# DA14681 register map
Vendor: Dialog; Series: DA14681; File version: 1.2
CPU: CM0 r1p0, little endian, MPU, FPU, 3 interrupt priority bits
Registers are 16-bit, read-write, reset 0x0 unless marked. A register's access mark holds for its fields unless they carry their own. Offsets are from the block's base; [hi:lo] are bit positions; {n}, {i} and the like mark numbered series; 'fields as' and 'values as' point back to an identical list.

## FTDF — FTDF registers
Base 0x40080000
{0x0+0x80*i} FTDF_TX_FIFO_{i}_0_REG 32-bit (reset mask 0x7FFFFFFF) (i=0..3) — Address transmit fifo {i}
  [31:0] TX_FIFO — Transmit fifo buffer, contains 32 addresses per entry (32b x 32a = 128B). There are 4 entries supported.
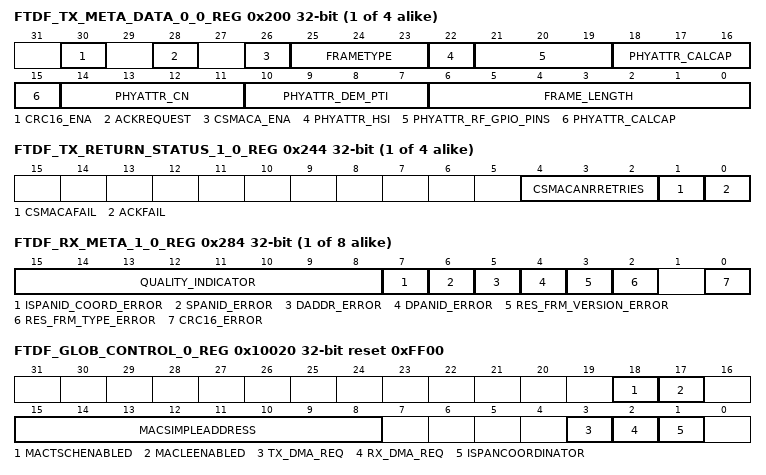
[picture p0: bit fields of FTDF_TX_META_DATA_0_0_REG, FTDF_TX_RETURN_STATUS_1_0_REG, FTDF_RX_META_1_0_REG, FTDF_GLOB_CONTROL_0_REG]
{0x200+0x10*i} FTDF_TX_META_DATA_0_{i}_REG 32-bit (i=0..3) — Transmit metadata register {i}
  [30] CRC16_ENA — Indicates whether CRC16 insertion must be enabled or not. 0 : No hardware inserted CRC16 1 : Hardware inserts CRC16
  [28] ACKREQUEST — Indicates whether an acknowledge is expected from the recipient of this packet.
  [26] CSMACA_ENA — Indicates whether a CSMA-CA is required for the transmission of this packet.
  [25:23] FRAMETYPE — Data/Cmd/Ack etc. Also indicate wakeup frame
  [22] PHYATTR_HSI — HighSide injection.
  [21:19] PHYATTR_RF_GPIO_PINS — Slot-basis signals mapped on GPIO via PPA.
  [18:15] PHYATTR_CALCAP — CalCap value.
  [14:11] PHYATTR_CN — Channel Number.
  [10:7] PHYATTR_DEM_PTI — DEM packet information.
  [6:0] FRAME_LENGTH
{0x204+0x10*i} FTDF_TX_META_DATA_1_{i}_REG 32-bit (i=0..3) — Transmit metadata register {i}
  [7:0] MACSN — Sequence Number of this packet.
{0x240+0x10*i} FTDF_TX_RETURN_STATUS_0_{i}_REG 32-bit (reset mask 0x7FFFFFFF) (i=0..3) — Transmit status register {i}
  [31:0] TXTIMESTAMP ro — Transmit Timestamp The TimeStamp of the transmitted packet.
{0x244+0x10*i} FTDF_TX_RETURN_STATUS_1_{i}_REG 32-bit (i=0..3) — Transmit status register {i}
  [4:2] CSMACANRRETRIES ro — Number of CSMA-CA retries
  [1] CSMACAFAIL ro — CSMA-CA status 0 : SUCCESS 1 : FAIL
  [0] ACKFAIL ro — Acknowledgement status 0 : SUCCESS 1 : FAIL
{0x280+0x10*i} FTDF_RX_META_0_{i}_REG 32-bit (reset mask 0x7FFFFFFF) (i=0..7) — Receive metadata register {i}
  [31:0] RX_TIMESTAMP ro — Timestamp taken when frame was received
{0x284+0x10*i} FTDF_RX_META_1_{i}_REG 32-bit (i=0..7) — Receive metadata register {i}
  [15:8] QUALITY_INDICATOR ro — Link Quality Indication # $software_scratch@retention_ram # TX ram not used by hardware, can be used by software as scratch ram with retention.
  [7] ISPANID_COORD_ERROR ro — Received frame not for PAN coordinator, applicable when frame is not discarded
  [6] SPANID_ERROR ro — PAN ID error, applicable when frame is not discarded
  [5] DADDR_ERROR ro — D Address error, applicable when frame is not discarded
  [4] DPANID_ERROR ro — D PAN ID error, applicable when frame is not discarded
  [3] RES_FRM_VERSION_ERROR ro — Not supported frame version error, applicable when frame is not discarded.
  [2] RES_FRM_TYPE_ERROR ro — Not supported frame type error, applicable when frame is not discarded
  [0] CRC16_ERROR ro — CRC error, applicable for transparent mode only
0x8000 FTDF_RX_FIFO_0_0_REG 32-bit (reset mask 0x7FFFFFFF) — Address receive fifo 0
  [31:0] RX_FIFO — Receive fifo ram, contains 32 addresses per entry (32b x 32a = 128B). There are 8 entries supported.
{0x8000+0x80*i} FTDF_RX_FIFO_{i}_0_REG 32-bit (reset mask 0x7FFFFFFF) (i=1..7) — Address transmit fifo {i}
  fields as FTDF_RX_FIFO_0_0_REG
{0x10000+4i} FTDF_REL_NAME_{i}_REG 32-bit (reset mask 0x7FFFFFFF) (i=0..3) — Name of the release
  [31:0] REL_NAME ro
{0x10010+4i} FTDF_BUILDTIME_{i}_REG 32-bit (reset mask 0x7FFFFFFF) (i=0..3) — Build time
  [31:0] BUILDTIME ro — Build time of device
0x10020 FTDF_GLOB_CONTROL_0_REG 32-bit reset 0xFF00 — Global control register
  [18] MACTSCHENABLED — If set, TSCH mode is enabled
  [17] MACLEENABLED — If set, Low Energy mode is enabled
  [15:8] MACSIMPLEADDRESS — Simple address of the PAN coordinator
  [3] TX_DMA_REQ — Source of the TX_DMA_REQ output of this block.
  [2] RX_DMA_REQ — Source of the RX_DMA_REQ output of this block.
  [1] ISPANCOORDINATOR — Enable/disable receiver check on address fields (0=enabled, 1=disabled)
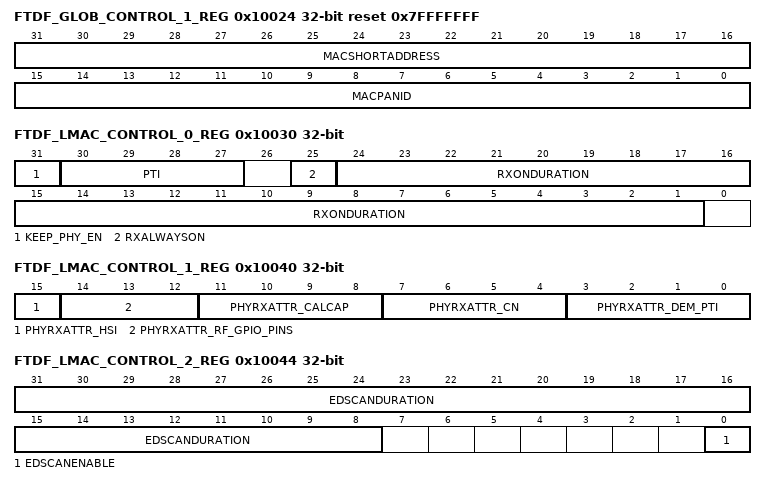
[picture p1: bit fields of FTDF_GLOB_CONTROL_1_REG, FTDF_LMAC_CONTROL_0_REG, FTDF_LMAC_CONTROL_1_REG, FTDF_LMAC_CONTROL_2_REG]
0x10024 FTDF_GLOB_CONTROL_1_REG 32-bit reset 0x7FFFFFFF (reset mask 0x7FFFFFFF) — Global control register
  [31:16] MACSHORTADDRESS — The values 0xFFFF and 0xFFFE indicate that no IEEE Short Address is available. The latter one is used if the device i
  [15:0] MACPANID — The values 0xFFFF indicates that the device is not associated
0x10028 FTDF_GLOB_CONTROL_2_REG 32-bit reset 0x7FFFFFFF (reset mask 0x7FFFFFFF) — Global control register
  [31:0] AEXTENDEDADDRESS_L — Unique device address, lower 32 bit
0x1002C FTDF_GLOB_CONTROL_3_REG 32-bit reset 0x7FFFFFFF (reset mask 0x7FFFFFFF) — Global control register
  [31:0] AEXTENDEDADDRESS_H — Unique device address, higher 16 bit
0x10030 FTDF_LMAC_CONTROL_0_REG 32-bit (reset mask 0x7FFFFFFF) — Lmac control register
  [31] KEEP_PHY_EN — When the transmit or receive action is ready (LmacReady4Sleep will is set), the phy_en signal is cleared unless the control register keep_phy_en is set. When the control register keep_phy_en is set, the signal phy_en shall remain being set until the keep_phy_en is cleared.
  [30:27] PTI — Info to arbiter if phy_en is set
  [25] RXALWAYSON — If set, the receiver shall be always on if RxEnable is set
  [24:1] RXONDURATION — Time the Rx must be on
0x10034 FTDF_TXPIPEPROPDELAY_REG 32-bit — Prop delay transmit register
  [7:0] TXPIPEPROPDELAY — Prop delay of tx pipe, start to DPHY
0x10038 FTDF_MACACKWAITDURATION_REG 32-bit reset 0x36 — Maximum time to wait for a ACK
  [7:0] MACACKWAITDURATION — Max time to wait for a (normal) ACK
0x1003C FTDF_MACENHACKWAITDURATION_REG 32-bit reset 0x360 — Maximum time to wait for an enhanced ACK frame
  [15:0] MACENHACKWAITDURATION — The maximum time (in s) to wait for an enhanced acknowledgement frame
0x10040 FTDF_LMAC_CONTROL_1_REG 32-bit — Lmac control register
  [15] PHYRXATTR_HSI — HighSide injection.
  [14:12] PHYRXATTR_RF_GPIO_PINS — Slot-basis signals mapped on GPIO via PPA.
  [11:8] PHYRXATTR_CALCAP — CalCap value.
  [7:4] PHYRXATTR_CN — Channel Number.
  [3:0] PHYRXATTR_DEM_PTI — DEM packet information.
0x10044 FTDF_LMAC_CONTROL_2_REG 32-bit (reset mask 0x7FFFFFFF) — Lmac control register
  [31:8] EDSCANDURATION — Length of ED scan
  [0] EDSCANENABLE — if set, Energy Detect scan will be done
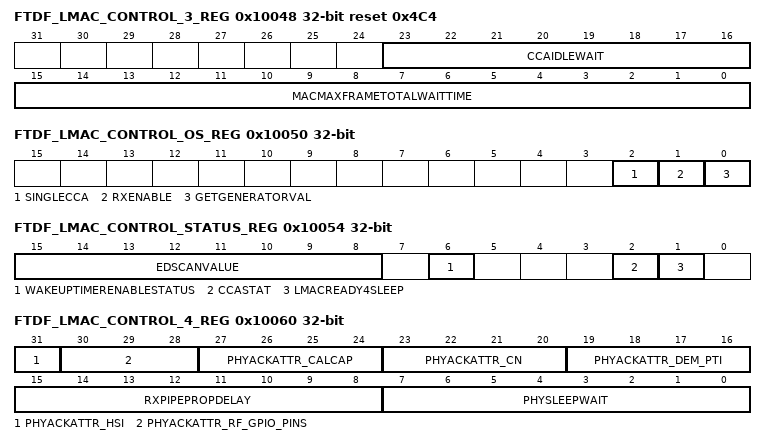
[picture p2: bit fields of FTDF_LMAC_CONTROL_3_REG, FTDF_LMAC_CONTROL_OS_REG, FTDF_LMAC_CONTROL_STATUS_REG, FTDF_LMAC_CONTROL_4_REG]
0x10048 FTDF_LMAC_CONTROL_3_REG 32-bit reset 0x4C4 — Lmac control register
  [23:16] CCAIDLEWAIT — Time to wait after CCA returned "medium idle" before starting TX-ON (in us). Note: not applicable in TSCH mode since there macTSRxTx shall be used.
  [15:0] MACMAXFRAMETOTALWAITTIME — Max time to wait for a requested Data Frame or an announced broadcast frame
0x10050 FTDF_LMAC_CONTROL_OS_REG 32-bit — Lmac control register
  [2] SINGLECCA wo — If set, a single CCA will be performed.
  [1] RXENABLE wo — If set, receiving data may be done
  [0] GETGENERATORVAL wo — If set, the current values of WU gen and TS gen will be captured.
0x10054 FTDF_LMAC_CONTROL_STATUS_REG 32-bit — Lmac status register
  [15:8] EDSCANVALUE ro — Result of ED scan.
  [6] WAKEUPTIMERENABLESTATUS ro — Status of WakeupTimerEnable after being clocked by LP_CLK (showing it's effective value).
  [2] CCASTAT ro — Value single CCA when CCAstat_e is set.
  [1] LMACREADY4SLEEP ro — Indicates that the LMAC is ready to go to sleep.
0x10058 FTDF_EVENTCURRVAL_REG 32-bit (reset mask 0x7FFFFFFF) — Value of event generator
  [31:0] EVENTCURRVAL ro — Value of captured Event generator
0x1005C FTDF_TIMESTAMPCURRVAL_REG 32-bit (reset mask 0x7FFFFFFF) — Value of timestamp generator
  [31:0] TIMESTAMPCURRVAL ro — Value of captured TS gen
0x10060 FTDF_LMAC_CONTROL_4_REG 32-bit (reset mask 0x7FFFFFFF) — Lmac control register
  [31] PHYACKATTR_HSI — HighSide injection.
  [30:28] PHYACKATTR_RF_GPIO_PINS — Slot-basis signals mapped on GPIO via PPA.
  [27:24] PHYACKATTR_CALCAP — CalCap value.
  [23:20] PHYACKATTR_CN — Channel Number.
  [19:16] PHYACKATTR_DEM_PTI — DEM packet information.
  [15:8] RXPIPEPROPDELAY — The control register RxPipePropDelay indicates the propagation delay in ~s of the Rx pipeline between the last symbol being captured at the DPHY interface and the "data valid" indication to the LMAC controller.
  [7:0] PHYSLEEPWAIT — Time between negate and assert PHY_EN When the signal phy_en is deasserted, it will not be asserted within the time phySleepWait. This time is indicated by the control register phySleepWait (resolution: ~s).
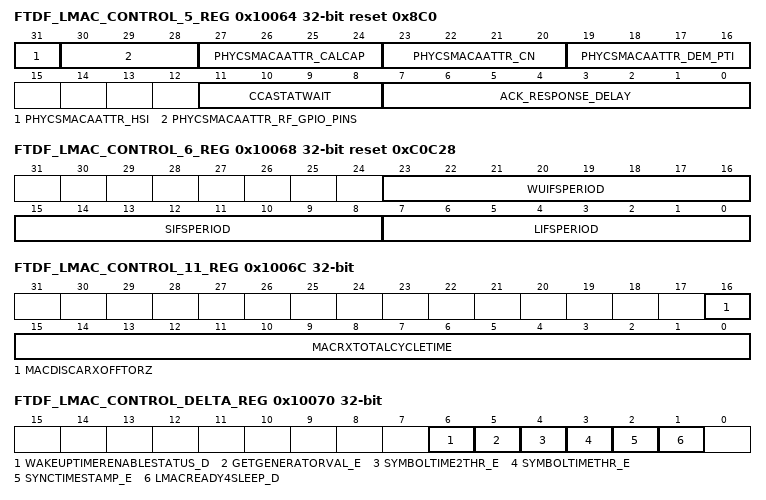
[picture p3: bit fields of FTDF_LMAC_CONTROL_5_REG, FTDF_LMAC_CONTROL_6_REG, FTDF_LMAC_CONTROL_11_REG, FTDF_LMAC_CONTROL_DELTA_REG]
0x10064 FTDF_LMAC_CONTROL_5_REG 32-bit reset 0x8C0 (reset mask 0x7FFFFFFF) — Lmac control register
  [31] PHYCSMACAATTR_HSI — HighSide injection.
  [30:28] PHYCSMACAATTR_RF_GPIO_PINS — Slot-basis signals mapped on GPIO via PPA.
  [27:24] PHYCSMACAATTR_CALCAP — CalCap value.
  [23:20] PHYCSMACAATTR_CN — Channel Number.
  [19:16] PHYCSMACAATTR_DEM_PTI — DEM packet information.
  [11:8] CCASTATWAIT — The output CCASTAT is valid after 8 symbols + phyRxStartup. The 8 symbols are programmable by control registerCcaStatWait[4] in symbol timesl. Default value is 8d.
  [7:0] ACK_RESPONSE_DELAY — In order to have some flexibility the control register Ack_Response_Delay indicates the Acknowledge response time in ~s. The default value shall is 192 ~s (12 symbols).
0x10068 FTDF_LMAC_CONTROL_6_REG 32-bit reset 0xC0C28 — Lmac control register
  [23:16] WUIFSPERIOD — The WakeUp IFS period is programmable by WUifsPeriod (in symbols). The default is 12 symbols (192 ~s).
  [15:8] SIFSPERIOD — The SIFS period is programmable by SifsPeriod (in symbols). The default is 12 symbols (192 ~s).
  [7:0] LIFSPERIOD — The LIFS period is programmable by LifsPeriod (in symbols). The default is 40 symbols (640 ~s),
0x1006C FTDF_LMAC_CONTROL_11_REG 32-bit — Lmac control register
  [16] MACDISCARXOFFTORZ — This switching off and on of the PHY Rx can be disabled whith the control register macDisCaRxOfftoRZ. 0 : Disabled 1 : Enabled
  [15:0] MACRXTOTALCYCLETIME — In order to make it easier to calculate if it is efficient to disable and enable the PHY Rx until the RZ time is reached, a control register indicates the time needed to disable and enable the PHY Rx: macRxTotalCycleTime (resolution in 10 sym)
0x10070 FTDF_LMAC_CONTROL_DELTA_REG 32-bit — Lmac delta control register
  [6] WAKEUPTIMERENABLESTATUS_D — Delta which indicates that WakeupTimerEnableStatus has changed
  [5] GETGENERATORVAL_E — Event which indicates the getGeneratorVal request is completed
  [4] SYMBOLTIME2THR_E — Event that symboltime counter matched SymbolTime2Thr
  [3] SYMBOLTIMETHR_E — Event that symboltime counter matched SymbolTimeThr
  [2] SYNCTIMESTAMP_E — The SyncTimeStamp_e event is set when the TimeStampgenerator is loaded with SyncTimeStampVal. This occurs at the rising edge of lp_clk when SyncTimeStampEna is set and the value of the Event generator is equal to the value SyncTimestampThr.
  [1] LMACREADY4SLEEP_D — Delta bit for register "LmacReady4sleep"
0x10074 FTDF_TIMESTAMPCURRPHASEVAL_REG 32-bit — Value of timestamp generator phase within a symbol
  [7:0] TIMESTAMPCURRPHASEVAL ro — Value of captured TS gen phase within a symbol
0x10078 FTDF_MACTSTXACKDELAYVAL_REG 32-bit — Time left until next ACK is sent (us)
  [15:0] MACTSTXACKDELAYVAL ro — The time in us left until the ack frame is sent by the lmac
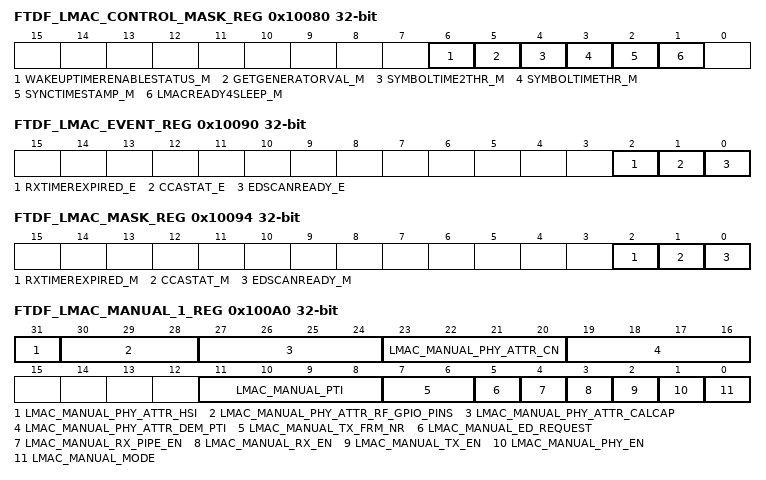
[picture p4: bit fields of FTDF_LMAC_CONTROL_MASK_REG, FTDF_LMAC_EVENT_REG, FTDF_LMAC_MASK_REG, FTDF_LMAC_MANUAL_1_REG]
0x10080 FTDF_LMAC_CONTROL_MASK_REG 32-bit — Lmac mask control register
  [6] WAKEUPTIMERENABLESTATUS_M — Mask for WakeupTimerEnableStatus_d
  [5] GETGENERATORVAL_M — Mask for getGeneratorVal_e
  [4] SYMBOLTIME2THR_M — Mask for SymbolTime2Thr_e
  [3] SYMBOLTIMETHR_M — Mask for SymbolTimeThr_e
  [2] SYNCTIMESTAMP_M — Mask bit for event register SyncTimeStamp_e.
  [1] LMACREADY4SLEEP_M — Mask bit for delta bit "LmacReady4sleep_d"
0x10090 FTDF_LMAC_EVENT_REG 32-bit — Lmac event regsiter
  [2] RXTIMEREXPIRED_E — Set if one of the timers enabling the RX-ON mode expires without having received any valid frame
  [1] CCASTAT_E — If set, the single CCA is ready
  [0] EDSCANREADY_E — The event EdScanReady_e is set to notify that the ED scan is ready.
0x10094 FTDF_LMAC_MASK_REG 32-bit — Lmac mask register
  [2] RXTIMEREXPIRED_M — Mask bit for event "RxTimerExpired_e"
  [1] CCASTAT_M — Mask bit for event "CCAstat_e"
  [0] EDSCANREADY_M — Mask bit for event "EdScanReady_e"
0x100A0 FTDF_LMAC_MANUAL_1_REG 32-bit (reset mask 0x7FFFFFFF) — Lmax manual PHY register
  [31] LMAC_MANUAL_PHY_ATTR_HSI — HighSide injection.
  [30:28] LMAC_MANUAL_PHY_ATTR_RF_GPIO_PINS — Slot-basis signals mapped on GPIO via PPA.
  [27:24] LMAC_MANUAL_PHY_ATTR_CALCAP — CalCap value.
  [23:20] LMAC_MANUAL_PHY_ATTR_CN — Channel Number.
  [19:16] LMAC_MANUAL_PHY_ATTR_DEM_PTI — DEM packet information.
  [11:8] LMAC_MANUAL_PTI — lmac_manual_pti controls the PTI interface signal when lmac_manual_mode is set
  [7:6] LMAC_MANUAL_TX_FRM_NR — lmac_manual_tx_frm_nr controls the entry in the tx buffer to be transmitted.
  [5] LMAC_MANUAL_ED_REQUEST — lmac_manual_ed_request controls the ED_REQUEST interface signal when lmac_manual_mode is set
  [4] LMAC_MANUAL_RX_PIPE_EN — lmac_manual_rx_pipe_en controls the rx_enable signal towards the rx pipeline when lmac_manual_mode is set
  [3] LMAC_MANUAL_RX_EN — lmac_manual_rx_en controls the RX_EN interface signal when lmac_manual_mode is set
  [2] LMAC_MANUAL_TX_EN — lmac_manual_tx_en controls the TX_EN interface signal when lmac_manual_mode is set
  [1] LMAC_MANUAL_PHY_EN — lmac_manual_phy_en controls the PHY_EN interface signal when lmac_manual_mode is set
  [0] LMAC_MANUAL_MODE — If the control register lmac_manual_mode is set, the LMAC controller control signals should be controlled by the lmac_manual_control registers
0x100A4 FTDF_LMAC_MANUAL_OS_REG 32-bit — One shot register triggers transmission in manual mode
  [0] LMAC_MANUAL_TX_START wo — One shot register which triggers the transmission of a frame from the tx buffer in lmac_manual_mode
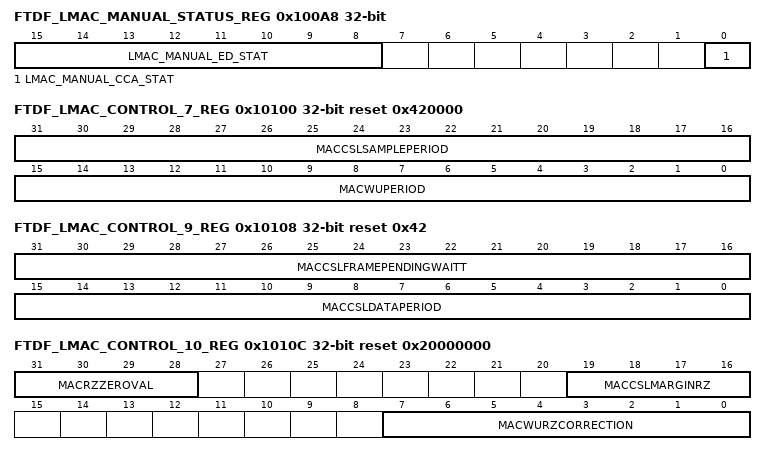
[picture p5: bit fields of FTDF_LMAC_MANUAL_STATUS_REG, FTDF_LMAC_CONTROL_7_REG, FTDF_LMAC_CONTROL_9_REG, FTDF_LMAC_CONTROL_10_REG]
0x100A8 FTDF_LMAC_MANUAL_STATUS_REG 32-bit — Lmac status register in manual mode
  [15:8] LMAC_MANUAL_ED_STAT ro — lmac_manual_ed_stat shows the status of the ED_STAT interface signal.
  [0] LMAC_MANUAL_CCA_STAT ro — lmac_manual_cca_stat shows the status of the CCA_STAT
0x10100 FTDF_LMAC_CONTROL_7_REG 32-bit reset 0x420000 (reset mask 0x7FFFFFFF) — Lmac control register
  [31:16] MACCSLSAMPLEPERIOD — When performing a idle listening, the receiver is enabled for at least macCSLsamplePeriod (in symbols).
  [15:0] MACWUPERIOD — Wake-up duration in symbols.
0x10104 FTDF_LMAC_CONTROL_8_REG 32-bit (reset mask 0x7FFFFFFF) — Lmac control register
  [31:0] MACCSLSTARTSAMPLETIME — The control register macCSLstartSampleTime indicates the TimeStamp generator time (in symbols) when to start listening (called "idle listening").
0x10108 FTDF_LMAC_CONTROL_9_REG 32-bit reset 0x42 (reset mask 0x7FFFFFFF) — Lmac control register
  [31:16] MACCSLFRAMEPENDINGWAITT — If a non Wake-up frame with Frame Pending bit = '1' is received, the receiver is enabled for at least an extra period of macCSLFramePendingWaitT (in symbols) after the end of the received frame. The time the Enhanced ACK transmission lasts (if applicable) is included in this time.
  [15:0] MACCSLDATAPERIOD — After the wake-up sequence a frame is expected, the receiver will be enabled for at least a period of macCSLdataPeriod (in symbols).
0x1010C FTDF_LMAC_CONTROL_10_REG 32-bit reset 0x20000000 (reset mask 0x7FFFFFFF) — Lmac control register
  [31:28] MACRZZEROVAL — If the current RZtime is less or Equal to macRZzeroVal an RZtime with value zero is inserted in the wakeup frame
  [19:16] MACCSLMARGINRZ — The UMAC can set the margin for the expected frame by control register macCSLmarginRZ (in 10 sym). So the LMAC will make sure the receiver is ready to receive data this amount of time earlier than to be expected by the received RZ time
  [7:0] MACWURZCORRECTION — This register shall be used if the Wake-up frame to be transmitted is larger than 15 octets. It shall indicate the amount of extra data in a Wake-up frame after the RZ position in the frame (in 10 sym).
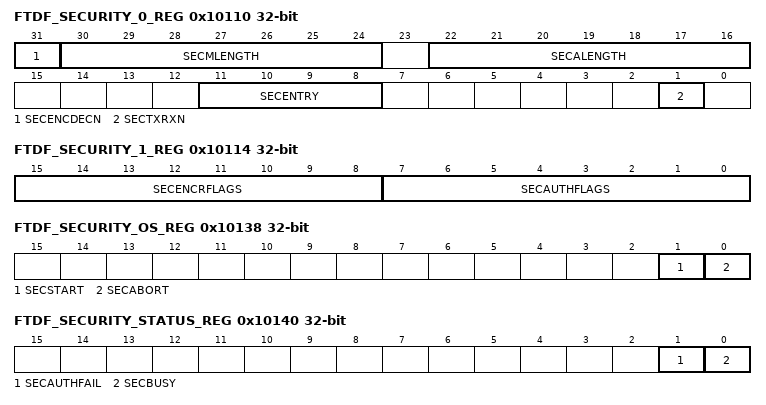
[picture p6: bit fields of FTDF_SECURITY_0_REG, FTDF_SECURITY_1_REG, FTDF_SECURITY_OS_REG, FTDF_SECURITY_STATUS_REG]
0x10110 FTDF_SECURITY_0_REG 32-bit (reset mask 0x7FFFFFFF) — Security register
  [31] SECENCDECN — The control register secEncDecn indicates whether to encrypt ('1') or decrypt ('0') the data.
  [30:24] SECMLENGTH — The length of the m_data is indicated by control register secMlength.
  [22:16] SECALENGTH — The length of the a_data is indicated by control register secAlength. The end of the a_data is the start point of the m_data. (So secAlength must also be set if security level==4)
  [11:8] SECENTRY — The UMAC shall indicate by control registers secEntry and secTxRxn which entry to use and if it's from the Tx or Rx buffer ('1' resp. '0').
  [1] SECTXRXN — See register "secEntry"
0x10114 FTDF_SECURITY_1_REG 32-bit — Security register
  [15:8] SECENCRFLAGS — Register secEncrFlags contain the encryption flags field. Bits [2:0] are the 3-bit encoding flags of a_data, the other bits msut be set to '0'.
  [7:0] SECAUTHFLAGS — Register secAuthFlags contains the authentication flags fields. bit[7] is '0' bit[6] is "A_data present" bit[5:3]: 3-bit security level of m_data bit[2:0]: 3-bit security level of a_data.
0x10118 FTDF_SECKEY_0_REG 32-bit (reset mask 0x7FFFFFFF) — Seckey register
  [31:0] SECKEY_0 — Registers secKey[0..3] contain the key to be used.
0x1011C FTDF_SECKEY_1_REG 32-bit (reset mask 0x7FFFFFFF) — Seckey register
  [31:0] SECKEY_1 — See register "secKey_0"
0x10120 FTDF_SECKEY_2_REG 32-bit (reset mask 0x7FFFFFFF) — SecKey register
  [31:0] SECKEY_2 — See register "secKey_0"
0x10124 FTDF_SECKEY_3_REG 32-bit (reset mask 0x7FFFFFFF) — Seckey register
  [31:0] SECKEY_3 — See register "secKey_0"
0x10128 FTDF_SECNONCE_0_REG 32-bit (reset mask 0x7FFFFFFF) — Nonce register used for encryption/decryption
  [31:0] SECNONCE_0 — Register secNonce[0..3] contains the Nonce to be used for encryption/decryption.
0x1012C FTDF_SECNONCE_1_REG 32-bit (reset mask 0x7FFFFFFF) — Nonce register used for encryption/decryption
  [31:0] SECNONCE_1 — See register "Nonce_0"
0x10130 FTDF_SECNONCE_2_REG 32-bit (reset mask 0x7FFFFFFF) — Nonce register used for encryption/decryption
  [31:0] SECNONCE_2 — See register "Nonce_0"
0x10134 FTDF_SECNONCE_3_REG 32-bit — Nonce register used for encryption/decryption
  [7:0] SECNONCE_3 — See register "Nonce_0"
0x10138 FTDF_SECURITY_OS_REG 32-bit — One shot register to start encryption/decryption
  [1] SECSTART wo — One_shot register to start the encryption, decryption and authentication support task.
  [0] SECABORT wo — See register "Nonce_0"
0x10140 FTDF_SECURITY_STATUS_REG 32-bit — Security status register
  [1] SECAUTHFAIL ro — In case of decryption, the status bit secAuthFail will be set when the authentication has failed.
  [0] SECBUSY ro — Register "secBusy" indicates if the encryption/decryption process is still running.
0x10150 FTDF_SECURITY_EVENT_REG 32-bit — security event register
  [0] SECREADY_E — The Event bit secReady_e is set when the authentication process is ready (i.e. secBusy is cleared). This Event shall contribute to the gen_irq.
0x10154 FTDF_SECURITY_EVENTMASK_REG 32-bit — security event mask register
  [0] SECREADY_M — Mask bit for event "secReady_e".
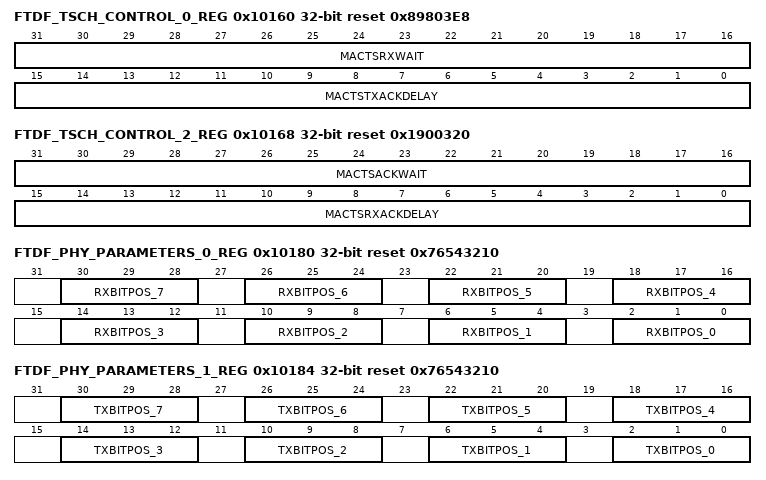
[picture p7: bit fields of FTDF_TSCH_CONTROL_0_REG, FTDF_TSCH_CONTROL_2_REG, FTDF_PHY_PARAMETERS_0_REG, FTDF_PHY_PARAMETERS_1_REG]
0x10160 FTDF_TSCH_CONTROL_0_REG 32-bit reset 0x89803E8 (reset mask 0x7FFFFFFF) — Lmac tsch control register
  [31:16] MACTSRXWAIT — The times to wait for start of frame
  [15:0] MACTSTXACKDELAY — End of Rx frame to start of Ack
0x10164 FTDF_TSCH_CONTROL_1_REG 32-bit reset 0xC0 — Lmac tsch control register
  [15:0] MACTSRXTX — The time between the CCA and the TX of a frame
0x10168 FTDF_TSCH_CONTROL_2_REG 32-bit reset 0x1900320 (reset mask 0x7FFFFFFF) — Lmac tsch control register
  [31:16] MACTSACKWAIT — The minimum time to wait for start of an Acknowledgement
  [15:0] MACTSRXACKDELAY — End of frame to when the transmitter shall listen for Acknowledgement
0x10180 FTDF_PHY_PARAMETERS_0_REG 32-bit reset 0x76543210 — Lmac PHY parameter register
  [4n+2:4n] RXBITPOS_{n} (n=1..7) — See rxBitPos_0
  [2:0] RXBITPOS_0 — Control rxBitPos(8)(3) controls the position that a bit should have at the DPHY interface. So the default values are rxBitPos_0 = 0, rxBitPos_1 = 1, rxBitPos_2 = 2, etc. Note1 that this is a conversion from rx DPHY interface to the internal data byte So for(n=7;n>=0;n--) rx_data(n) = dphy_bit(tx_BitPos(n)) endfor Note2 that rxBitPos and txBitPos must have inverse functions.
0x10184 FTDF_PHY_PARAMETERS_1_REG 32-bit reset 0x76543210 — Lmac PHY parameter register
  [4n+2:4n] TXBITPOS_{n} (n=1..7) — See txBitPos_0
  [2:0] TXBITPOS_0 — Control txBitPos(8)(3) controls the position that a bit should have at the DPHY interface. So the default values are txBitPos_0 = 0, txBitPos_1 = 1, txBitPos_2 = 2, etc. Note1 that this is a conversion from internal data byte to the DPHY interface. So for(n=7;n>=0;n--) tx_dphy_bit(n) = tx_data(tx_BitPos(n)) endfor Note2 that txBitPos and rxBitPos must have inverse functions.
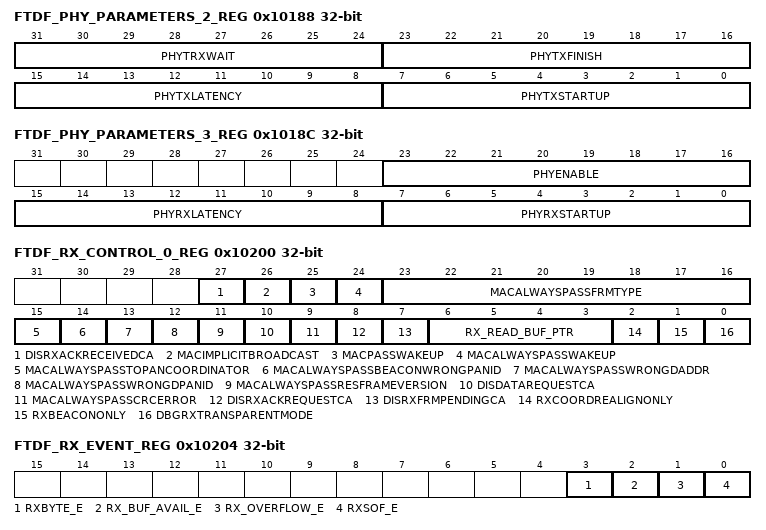
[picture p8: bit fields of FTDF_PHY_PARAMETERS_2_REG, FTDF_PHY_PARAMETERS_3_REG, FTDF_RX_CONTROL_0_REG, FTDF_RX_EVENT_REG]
0x10188 FTDF_PHY_PARAMETERS_2_REG 32-bit (reset mask 0x7FFFFFFF) — Lmac PHY parameter register
  [31:24] PHYTRXWAIT — Phy wait time between TX_EN/RX_EN
  [23:16] PHYTXFINISH — Phy wait time before deasserting TX_EN
  [15:8] PHYTXLATENCY — Phy delay between DPHY i/f and air
  [7:0] PHYTXSTARTUP — Phy wait time before transmission
0x1018C FTDF_PHY_PARAMETERS_3_REG 32-bit — Lmac PHY parameter register
  [23:16] PHYENABLE — Asserting the DPHY interface signals TX_EN or RX_EN does not take place within the time phyEnable after asserting the signal phy_en. (resolution: ~s).
  [15:8] PHYRXLATENCY — Phy delay between air and DPHY i/f
  [7:0] PHYRXSTARTUP — Phy wait time before receiving
0x10200 FTDF_RX_CONTROL_0_REG 32-bit — Receive control register
  [27] DISRXACKRECEIVEDCA — If set, the LMAC controller shall ignore all consequent actions upon a set AR bit in the transmitted frame
  [26] MACIMPLICITBROADCAST — If set, Frame Version 2 frames without Daddr or DPANId shall be accepted.
  [25] MACPASSWAKEUP — If set, WakeUp frames will not be reported but will be put into the Rx buffer.
  [24] MACALWAYSPASSWAKEUP — If the control register macAlwaysPassWakeUp is set, received Wake- up frames for this device are put into the Rx packet buffer without notifying the LMAC Controller.
  [23:16] MACALWAYSPASSFRMTYPE — The control registers macAlwaysPassFrmType[7:0], shall control if this Frame Type shall be dropped. If a bit is set, the Frame Type corresponding with the bit position is not dropped, even in case of a CRC error. Example: if bit 1 is set, Frame Type 1 shall not be dropped. The error shall be reported in the Rx meta data
  [15] MACALWAYSPASSTOPANCOORDINATOR — When the control register macAlwaysPassToPanCoordinator is set, the frame is not dropped due to a span_coord_error. However, in case of an FCS error, the packet is dropped.
  [14] MACALWAYSPASSBEACONWRONGPANID — If the control register macAlwaysPassBeaconWrongPANId is set, the frame is not dropped in case of a mismatch in PAN-ID, irrespective of the setting of RxBeaconOnly.
  [13] MACALWAYSPASSWRONGDADDR — If set, a packet with a wrong DAddr is not dropped
  [12] MACALWAYSPASSWRONGDPANID — If register macAlwaysPassWrongDPANId is set, packet with a wrong Destiantion PanID will not be dropped. However, in case of an FCS error, the packet is dropped.
  [11] MACALWAYSPASSRESFRAMEVERSION — If set, a packet with a reserved FrameVersion shall not be dropped
  [10] DISDATAREQUESTCA — When the control register DisDataRequestCa is set, the notification of the received Data Request is disabled.
  [9] MACALWAYSPASSCRCERROR — If set, a FCS error will not drop the frame
  [8] DISRXACKREQUESTCA — When the control register DisRxAckRequestca is set all consequent actions for a received Acknowledge Request bit are disabled.
  [7] DISRXFRMPENDINGCA — Whan the control register DisRxFrmPendingCa is set, the notification of the received FP bit to the LMAC Controller is disabled.
  [6:3] RX_READ_BUF_PTR — Indication where new data will be read All four bits shall be used when using these pointer values (0d - 15d). However, the Receive Packet buffer has a size of 8 entries. So reading the Receive Packet buffer entries shall use the mod8 of the pointer values.
  [2] RXCOORDREALIGNONLY — If set, only Coordinator Realignment frames are accepted
  [1] RXBEACONONLY — If set, only Beacons frames are accepted
  [0] DBGRXTRANSPARENTMODE — If set, Rx pipe is fully set in transparent mode (for debug purpose).
0x10204 FTDF_RX_EVENT_REG 32-bit — Receive event register
  [3] RXBYTE_E — Indicates the first byte of a new packet is received
  [2] RX_BUF_AVAIL_E — Indicates that a new packet is received
  [1] RX_OVERFLOW_E — Indicates that the Rx packet buffer has an overflowl
  [0] RXSOF_E — Set when RX_SOF has been detected.
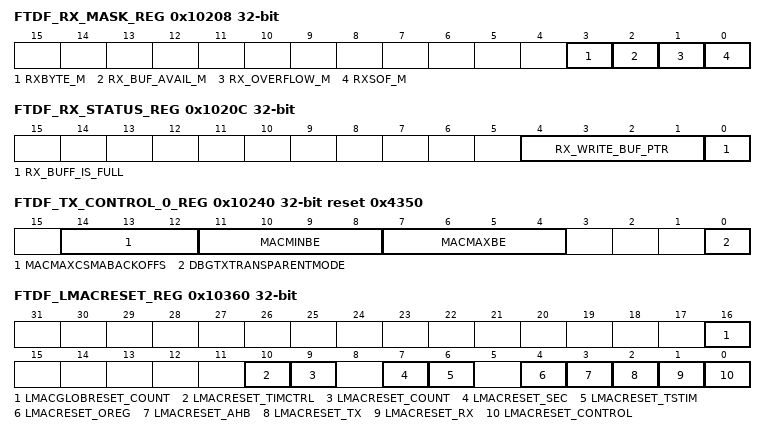
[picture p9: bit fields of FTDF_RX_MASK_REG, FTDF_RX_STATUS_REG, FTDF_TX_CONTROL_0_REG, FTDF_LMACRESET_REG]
0x10208 FTDF_RX_MASK_REG 32-bit — Receive event mask register
  [3] RXBYTE_M — Mask bit for event "rxbyte_e".
  [2] RX_BUF_AVAIL_M — Mask bit for event "rx_buf_avail_e".
  [1] RX_OVERFLOW_M — Mask bit for event " rx_overflow_e".
  [0] RXSOF_M — Mask bit for event "RxSof_e".
0x1020C FTDF_RX_STATUS_REG 32-bit — Receive status register
  [4:1] RX_WRITE_BUF_PTR ro — Indication where new data will be written. All four bits shall be used when using these pointer values (0d - 15d). However, the Receive Packet buffer has a size of 8 entries. So reading the Receive Packet buffer entries shall use the mod8 of the pointer values.
  [0] RX_BUFF_IS_FULL ro — Indicates that the Rx packet buffer is full
0x10210 FTDF_SYMBOLTIMESNAPSHOTVAL_REG 32-bit (reset mask 0x7FFFFFFF) — Value timestamp generator
  [31:0] SYMBOLTIMESNAPSHOTVAL ro — The Status register SymbolTimeSnapshotVal indicates the actual value of the TimeStamp generator.
0x10220 FTDF_RX_STATUS_DELTA_REG 32-bit — Receive status delta register
  [0] RX_BUFF_IS_FULL_D — Delta bit of status "rx_buff_is_full"
0x10224 FTDF_RX_STATUS_MASK_REG 32-bit — Receive status delta mask register
  [0] RX_BUFF_IS_FULL_M — Mask bit of status "rx_buff_is_full"
0x10240 FTDF_TX_CONTROL_0_REG 32-bit reset 0x4350 — Transmit control register
  [14:12] MACMAXCSMABACKOFFS — Maximum number of CSMA-CA backoffs (range 0-5)
  [11:8] MACMINBE — Minimum Backoff Exponent (range 0-macMaxBE)
  [7:4] MACMAXBE — Maximum Backoff Exponent (range 3-8)
  [0] DBGTXTRANSPARENTMODE — If 1, the MPDU octets pass transparently through the MAC in the transmit direction (for debug purpose).
0x10250 FTDF_FTDF_CE_REG 32-bit — Selection register events
  [5:0] FTDF_CE ro — Composite serveice request from ftdf macro (see FR0400 in v40.100.2.41.pdf) Bit 0 = unused Bit 1 = rx interrupts Bit 2 = unused Bit 3 = miscelaneous interrupts Bit 4 = tx interrupts Bit 5 = Reserved
0x10254 FTDF_FTDF_CM_REG 32-bit — Mask selection register events
  [5:0] FTDF_CM — mask bits for ftf_ce
0x10304 FTDF_SYNCTIMESTAMPTHR_REG 32-bit (reset mask 0x7FFFFFFF) — Threshold timestamp generator
  [31:0] SYNCTIMESTAMPTHR — Threshold for synchronize TS gen. Note that due to implementation this register may only be written once per two LP_CLK periods.
0x10308 FTDF_SYNCTIMESTAMPVAL_REG 32-bit (reset mask 0x7FFFFFFF) — Value timestamp generator
  [31:0] SYNCTIMESTAMPVAL — Value to sync TS gen with.
0x1030C FTDF_TIMER_CONTROL_1_REG 32-bit — Timer control register
  [1] SYNCTIMESTAMPENA — If set, the TimeStampThr is enabled to generate a sync of the TS gen.
0x10310 FTDF_MACTXSTDACKFRMCNT_REG 32-bit (reset mask 0x7FFFFFFF) — Transmitted acknowledgment frames
  [31:0] MACTXSTDACKFRMCNT ro — Standard Acknowledgment frames transmitted
0x10314 FTDF_MACRXSTDACKFRMOKCNT_REG 32-bit (reset mask 0x7FFFFFFF) — Received acknowledgment frames
  [31:0] MACRXSTDACKFRMOKCNT ro — Standard Acknowledgment frames received
0x10318 FTDF_MACRXADDRFAILFRMCNT_REG 32-bit (reset mask 0x7FFFFFFF) — Discarded frames register
  [31:0] MACRXADDRFAILFRMCNT ro — Frames discarded due to incorrect address or PAN Id
0x1031C FTDF_MACRXUNSUPFRMCNT_REG 32-bit (reset mask 0x7FFFFFFF) — Unsupported frames register
  [31:0] MACRXUNSUPFRMCNT ro — Frames which do pass the checks but are not supported
0x10320 FTDF_SYNCTIMESTAMPPHASEVAL_REG 32-bit — Timestamp phase value regsiter
  [7:0] SYNCTIMESTAMPPHASEVAL — Value to sync TS gen phase within a symbol with. Please note the +1 correction needed for most accurate result (+0.5 is than the average error, resulting is a just too fast clock).
0x10340 FTDF_MACFCSERRORCOUNT_REG 32-bit (reset mask 0x7FFFFFFF) — Lmac FCS error register
  [31:0] MACFCSERRORCOUNT ro — The number of received frames that were discarded due to an incorrect FCS.
0x10360 FTDF_LMACRESET_REG 32-bit — Lmax reset register
  [16] LMACGLOBRESET_COUNT wo — If set, the LMAC performance and traffic counters will be reset. Use this register for functionally reset these counters.
  [10] LMACRESET_TIMCTRL wo — LmacReset_count: A '1' Resets LMAC timing control block (for debug and MLME-reset)
  [9] LMACRESET_COUNT wo — LmacReset_count: A '1' Resets LMAC mac counters (for debug and MLME-reset)
  [7] LMACRESET_SEC wo — LmacReset_sec: A '1' Resets LMAC security (for debug and MLME-reset) #$LmacReset_wutim@on_off_regmap #LmacReset_wutim: A '1' Resets LMAC wake-up timer (for debug and MLME-reset)
  [6] LMACRESET_TSTIM wo — LmacReset_tstim: A '1' Resets LMAC timestamp timer (for debug and MLME-reset)
  [4] LMACRESET_OREG wo — LmacReset_oreg: A '1' Resets LMAC on_off regmap (for debug and MLME-reset) #$LmacReset_areg@on_off_regmap #LmacReset_areg: A '1' Resets LMAC always_on regmap (for debug and MLME-reset)
  [3] LMACRESET_AHB wo — LmacReset_ahb: A '1' Resets LMAC ahb interface (for debug and MLME-reset)
  [2] LMACRESET_TX wo — LmacReset_tx: A '1' Resets LMAC tx pipeline (for debug and MLME-reset)
  [1] LMACRESET_RX wo — LmacReset_rx: A '1' Resets LMAC rx pipeline (for debug and MLME-reset)
  [0] LMACRESET_CONTROL wo — LmacReset_control: A '1' Resets LMAC Controller (for debug and MLME-reset)
0x10380 FTDF_SYMBOLTIMETHR_REG 32-bit (reset mask 0x7FFFFFFF) — Symboltime threshold register 1
  [31:0] SYMBOLTIMETHR — Symboltime Threshold to generate a general interrupt
0x10384 FTDF_SYMBOLTIME2THR_REG 32-bit (reset mask 0x7FFFFFFF) — Symboltime threshold register 2
  [31:0] SYMBOLTIME2THR — Symboltime 2 Threshold to generate a general interrupt
0x10390 FTDF_DEBUGCONTROL_REG 32-bit — Debug control register
  [8] DBG_RX_INPUT — If set, the Rx debug interface will be selected as input for the Rx pipeline.
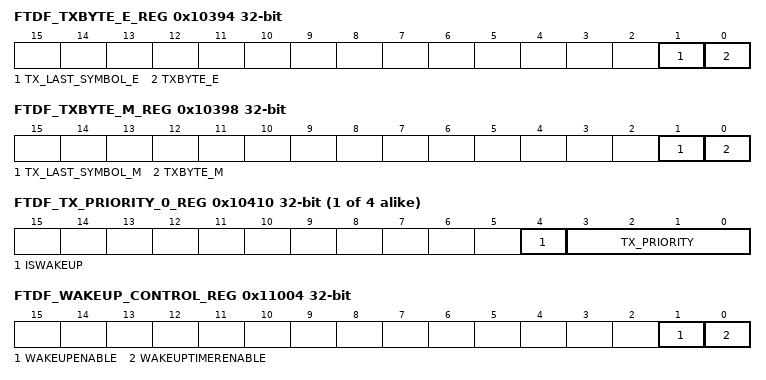
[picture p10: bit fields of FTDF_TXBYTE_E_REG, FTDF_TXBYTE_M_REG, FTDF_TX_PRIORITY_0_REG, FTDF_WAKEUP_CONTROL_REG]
0x10394 FTDF_TXBYTE_E_REG 32-bit — Transmit first byte register
  [1] TX_LAST_SYMBOL_E — Indicates the last symbol of a frame is transmitted
  [0] TXBYTE_E — Indicates the first byte of a frame is transmitted
0x10398 FTDF_TXBYTE_M_REG 32-bit — Transmit first byte mask register
  [1] TX_LAST_SYMBOL_M — Mask bit for event "tx_last_symbol_e".
  [0] TXBYTE_M — Mask bit for event "txbyte_e".
{0x10400+0x20*i} FTDF_TX_FLAG_S_{i}_REG 32-bit (i=0..3) — Transmit packet ready for transmission register {i}
  [0] TX_FLAG_STAT ro — Packet is ready for transmission
{0x10404+0x20*i} FTDF_TX_FLAG_CLEAR_E_{i}_REG 32-bit (i=0..3) — Clear flag register {i}
  [0] TX_FLAG_CLEAR_E — When the LMAC clears the tx_flag_stat status event bit tx_flag_clear_e is set.
0x10408 FTDF_TX_FLAG_CLEAR_M_0_REG 32-bit — Mask flag register 0
  [0] TX_FLAG_CLEAR_M — Mask bit for event "tx_flag_clear_e".
{0x10410+0x20*i} FTDF_TX_PRIORITY_{i}_REG 32-bit (i=0..3) — Transmit priority register {i}
  [4] ISWAKEUP — A basic wake-up frame can be generated by the UMAC in the Tx buffer. The meta data control bit IsWakeUp must be set to indicate that this is a Wake-up frame.
  [3:0] TX_PRIORITY — Priority of packet
0x10428 FTDF_TX_FLAG_CLEAR_M_1_REG 32-bit — Mask flag register 1
  [0] TX_FLAG_CLEAR_M — Mask bit for event "tx_flag_clear_e".
0x10448 FTDF_TX_FLAG_CLEAR_M_2_REG 32-bit — Clear flag register 2
  [0] TX_FLAG_CLEAR_M — Mask bit for event "tx_flag_clear_e".
0x10468 FTDF_TX_FLAG_CLEAR_M_3_REG 32-bit — Clear flag register 3
  [0] TX_FLAG_CLEAR_M — Mask bit for event "tx_flag_clear_e".
0x10480 FTDF_TX_SET_OS_REG 32-bit — One shot register to set flag
  [3:0] TX_FLAG_SET wo — To set tx_flag_stat
0x10484 FTDF_TX_CLEAR_OS_REG 32-bit — One shot register to clear flag
  [3:0] TX_FLAG_CLEAR wo — To clear tx_flag_stat
0x11000 FTDF_WAKEUPINTTHR_REG 32-bit (reset mask 0x7FFFFFFF) — Treshold value Wakeup timer
  [31:0] WAKEUPINTTHR — Threshold for wake-up interrupt.
0x11004 FTDF_WAKEUP_CONTROL_REG 32-bit — Wakeup timer vcontrol register
  [1] WAKEUPENABLE — If set, the WakeUpIntThr is enabled to generate an interrupt.
  [0] WAKEUPTIMERENABLE — A '1' Enables the wakeup timer. Note that in on_off_regmap, the register WakeupTimerEnableStatus shows the status of this register after being clocked by LP_CLK. Checking this register can be used as indication for software that this bit is effective in the desing.
